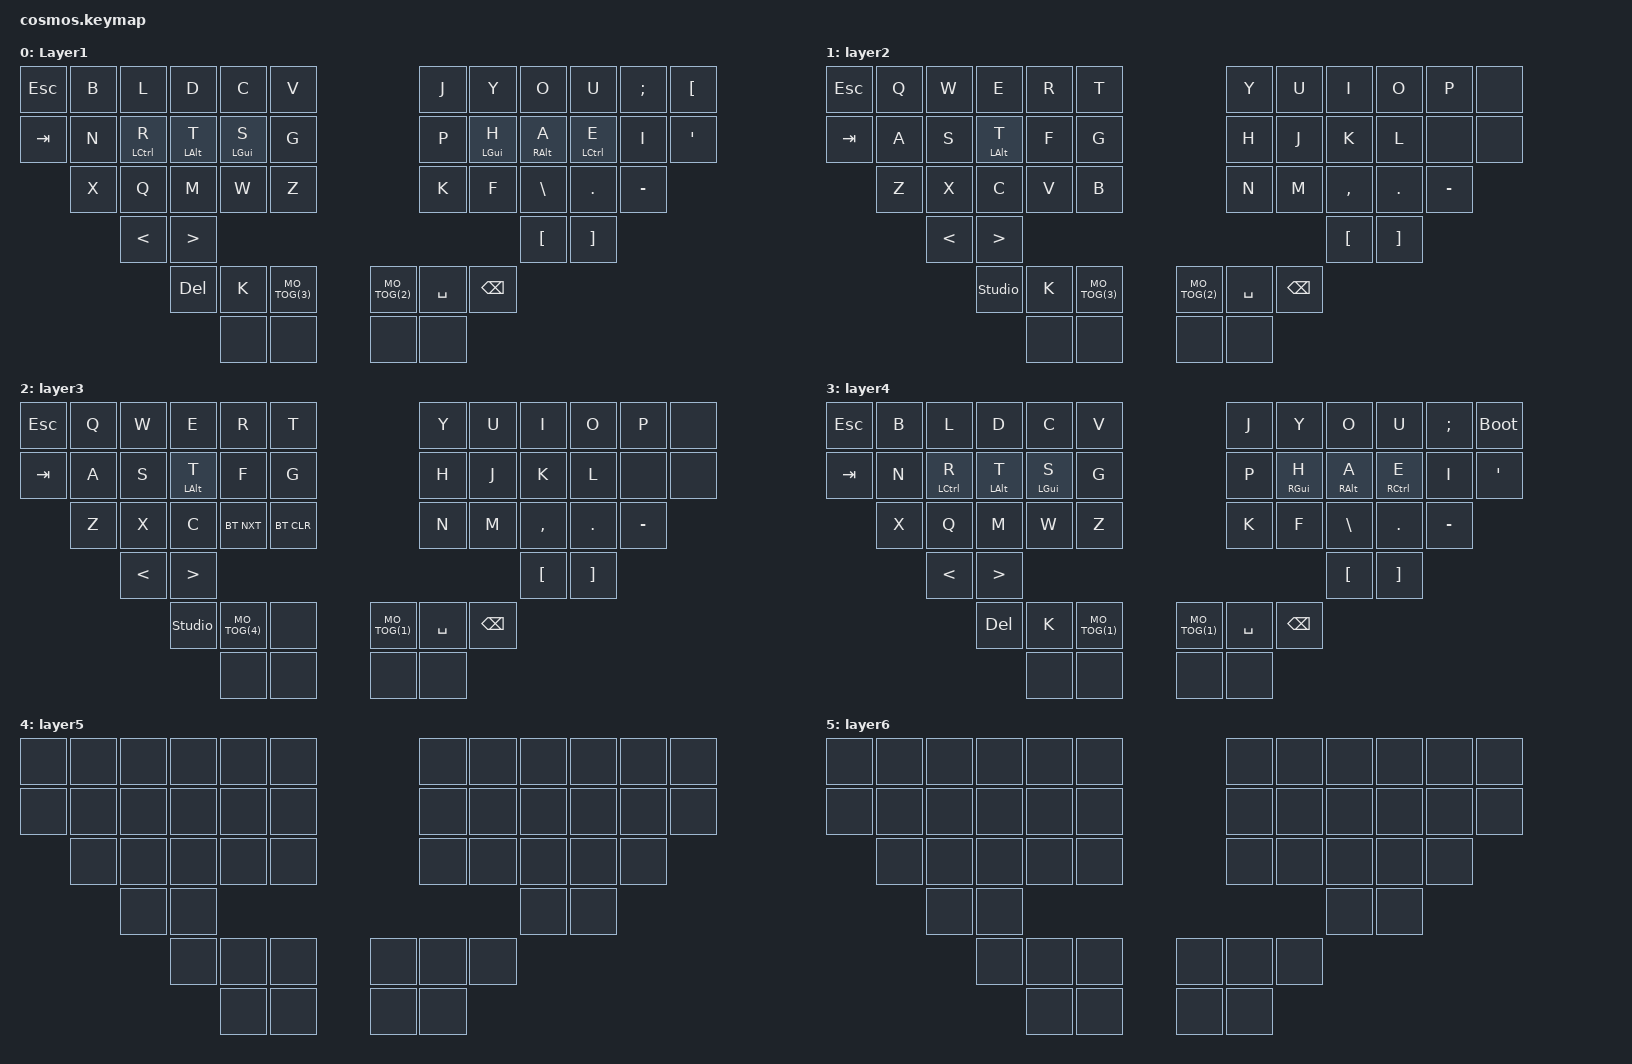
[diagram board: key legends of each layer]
#include <behaviors.dtsi>
#include <dt-bindings/zmk/keys.h>
#include <dt-bindings/zmk/bt.h>
#include <dt-bindings/zmk/mouse.h>
#include "./cosmos.h"

#define MO_TOG(layer) &mo_tog layer layer   // Macro to apply momentary-layer-on-hold/toggle-layer-on-tap to a specific layer

&mt {
    flavor = "tap-preferred";
    tapping_term_ms = <200>;
};

/ { 
	combos {
		compatible = "zmk,combos";

		combo_ent_right {
		    timeout-ms = <50>;
		    key-positions = <RB1 RB2>;
		    bindings = <&kp RET>;
		};
		combo_ent_left {
		    timeout-ms = <50>;
		    key-positions = <LB1 LB2>;
		    bindings = <&kp RET>;
		};

		combo_f {
		    timeout-ms = <50>;
		    key-positions = <LM1 LB1>;
		    bindings = <&kp F>;
		    layers = <0>;
		};
		combo_bksp {
		    timeout-ms = <50>;
		    key-positions = <RB2 RB3>;
		    bindings = <&kp BSPC>;
		};
		combo_bksp_left {
		    timeout-ms = <50>;
		    key-positions = <LB3 LB4>;
		    bindings = <&kp BSPC>;
		};

		combo_del_left {
		    timeout-ms = <50>;
		    key-positions = <LB2 LB3>;
		    bindings = <&kp DEL>;
		};
	};
	
	behaviors {
        bspc_del: backspace_delete {
            compatible = "zmk,behavior-mod-morph";
            #binding-cells = <0>;
            bindings = <&kp BACKSPACE>, <&kp DELETE>;
            mods = <(MOD_LSFT|MOD_RSFT)>;
        };
		mo_tog: behavior_mo_tog {
		    compatible = "zmk,behavior-hold-tap";
		    #binding-cells = <2>;
		    flavor = "hold-preferred";
		    tapping-term-ms = <200>;
		    bindings = <&mo>, <&tog>;
		};
		hm: homerow_mods {
		    compatible = "zmk,behavior-hold-tap";
		    label = "HOMEROW_MODS";
		    #binding-cells = <2>;
		    tapping-term-ms = <200>;
		    quick_tap_ms = <0>;
		    flavor = "tap-preferred";
		    bindings = <&kp>, <&kp>;
		};
		hs: homerow_shifts {
		    compatible = "zmk,behavior-hold-tap";
		    label = "HOMEROW_SHIFTS";
		    #binding-cells = <2>;
		    tapping-term-ms = <150>;
		    quick_tap_ms = <0>;
		    flavor = "balanced";
		    bindings = <&kp>, <&kp>;
		};
		hsl: homerow_shifts_layer {
		    compatible = "zmk,behavior-hold-tap";
		    label = "HOMEROW_SHIFTS_LAYER";
		    #binding-cells = <2>;
		    tapping-term-ms = <150>;
		    quick_tap_ms = <0>;
		    flavor = "balanced";
		    bindings = <&kp>, <&to>;
		};
		td: tapdance {
		    compatible = "zmk,behavior-hold-tap";
		    label = "TAPDANCE";
		    #binding-cells = <2>;
		    tapping-term-ms = <150>;
		    quick_tap_ms = <0>;
		    flavor = "tap-preferred";
		    bindings = <&kp>, <&kp>;
		};
		tl: layertap {
		    compatible = "zmk,behavior-hold-tap";
		    label = "LAYERTAP";
		    #binding-cells = <2>;
		    tapping-term-ms = <150>;
		    quick_tap_ms = <0>;
		    flavor = "tap-preferred";
		    bindings = <&to>, <&kp>;
		};
	};

        keymap {
                compatible = "zmk,keymap";

/*       		default_layer {
		bindings = <
		&kp TAB         &kp C           &kp L           &kp M           &trans 			&trans          &kp F           &kp U           &kp Z           &kp BKSP
		&kp I           &hm LCTL S      &hm LALT R      &hm LGUI T      &trans 			&trans          &hm RGUI N      &hm RALT K      &hm RCTL A      &kp O
		&hs LSHIFT Q    &kp V           &kp W           &kp D           &mt LC(LS(LALT)) SPC    &kp E           &kp H   &       kp Y            &td EXCL DOT    &hs RSHIFT X
          	                                        &mt LC(LS(LALT)) SPC    &trans                  &trans          &kp E
		>;*/
                
                Layer1 { // Layer 1, mallen klar. ska verkställas
                        bindings = <
                                // --------------------------------------------------------------
                             //|  ESC  |   B   |   L   |   D   |   C   |   V   |               |   J   |   Y   |   O   |    U   |    Ö   |    Å   |
                               &kp ESC   &kp B   &kp L   &kp D   &kp C   &kp V                   &kp J   &kp Y   &kp O   &kp U    &kp SEMI &kp LBKT

                             //|  TAB  |   N   |   R   |   T   |   S    |   G   |              |   P   |   H   |   A   |    E   |    I   |    Ä   |
                               &kp TAB   &kp N &hm LCTRL R &hm LALT T   &hm LGUI S   &kp G     &kp P   &hm LGUI H  &hm RALT A  &hm LCTRL E   &kp I &kp SINGLE_QUOTE
                          //      &kp TAB &kp N &hm LCTRL R &hm LALT T &hm LGUI S   &kp G        &none  &none  &none &none &none &none // &kp P &hm LGUI H &hm RALT A  &hm LCTRL E &kp I &kp SINGLE_QUOTE

                             //        |   X   |   Q   |   M   |   W   |   Z   |               |   K   |   F   |   '   |    ,   |    .   |
                                         &kp X   &kp Q   &kp M   &kp W   &kp Z                   &kp K   &kp F &kp BSLH &kp DOT &kp MINUS 

                             //                |   <   |   >   |                                               |   [   |    ]   |
                                                &kp LT   &kp GT                                                  &kp LBKT &kp RBKT


                             //                  |  DEL   |  SHIFT |  To 3 |               |  to 2  | SPACE | BKSP  |
                                                  &kp DEL  &kp K    MO_TOG(3)             MO_TOG(2) &kp SPACE &kp BSPC  

                             //                                  | none | none |               | none | none |
                                                                   &none   &none                  &none &none   
                        >;
                };

                /* Ben vallack kör följande på layer 1. Detta ska ändras till mina behov  left_layer {
		bindings = <
		&trans           &kp ATSN        &td LC(LG(LS(N4))) LS(N3)       &kp DLLR       &trans		&trans  &kp LS(COMMA)   &kp LS(DOT)     &kp CARET       &trans
		&kp TAB          &hm LCTL EQUAL  &hm LALT LA(RBKT)      &hm LGUI LA(LS(RBKT))   &trans 		&trans  &hm RGUI LBRC   &hm RALT RBRC   &hm RCTL PIPE   &kp AMPS
  		&hs LSHIFT TILDE &kp GRAVE 	 &kp LA(LBKT)           &kp LA(LS(LBKT))        &to 0 	        &to 2   &kp LPRN        &kp RPRN        &kp RBKT        &kp RSHIFT
					                                &to 0                   &trans  	&trans  &to 2 
		>;*/

                layer2 { // Specialtecken-lager
                        bindings = <
                                // --------------------------------------------------------------
                             //|  ESC  |   B   |   L   |   #   |  '|'  |   V   |               |   J   |   Y   |   O   |    U   |    Ö   |    Å   |
                               &kp ESC   &kp Q   &kp W   &kp E   &kp R   &kp T                   &kp Y   &kp U   &kp I   &kp O    &kp P    &none

                             //|  TAB  |   N   |   R   |   @   |   /   |   !   |              |   ?   |   (   |   [   |    {   |    <   |    Ä   |
                                &kp TAB  &kp A   &kp S &hm LALT T   &kp F   &kp G                   &kp H   &kp J   &kp K   &kp L    &none    &none

                             //    ;   |   X   |   Q   |   &   |   \   |   Z   |               |   K   |   )   |   ]   |    }   |    >   |
                                         &kp Z   &kp X   &kp C   &kp V   &kp B                   &kp N   &kp M &kp COMMA &kp DOT &kp MINUS 

                             //                |   <   |   >   |                                               |   [   |    ]   |
                                                &kp LT   &kp GT                                                  &kp LBKT &kp RBKT


                             //                  |  stdio ulck   |  SHIFT |  To 3 |               |  to 2  | SPACE | BKSP  |
                                                  &studio_unlock  &kp K    MO_TOG(3)             MO_TOG(2) &kp SPACE &kp BSPC  

                             //                                  | none | none |               | none | none |
                                                                   &none   &none                  &none &none   
                        >;
                };

                layer3 { // Nummer-lager
                        bindings = <
                                // --------------------------------------------------------------
                             //|  ESC  |   B   |   L   |   #   |  '|'  |   V   |               |   DIV   |   7   |   8   |    9   |    -   |    none   |
                               &kp ESC   &kp Q   &kp W   &kp E   &kp R   &kp T                   &kp Y   &kp U   &kp I   &kp O    &kp P    &none

                             //|  TAB  |   N   |   R   |   @   |   /   |   !   |              |   *   |   4   |   5   |    6   |    +   |    none   |
                                &kp TAB  &kp A   &kp S &hm LALT T   &kp F   &kp G                   &kp H   &kp J   &kp K   &kp L    &none    &none

                             //    ;   |   X   |   Q   |   &   | Bluetooth next |  bluetooth clear   |               |   K   |   1   |   2   |    3   |  ENTER |
                                         &kp Z   &kp X   &kp C   &bt BT_NXT   &bt BT_CLR                   &kp N   &kp M &kp COMMA &kp DOT &kp MINUS 

                             //                |   <   |   >   |                                               |   0   |    .   |
                                                &kp LT   &kp GT                                                  &kp LBKT &kp RBKT


                             //                  |  stdio ulck   | To 4 |   |               |  to 1  | SPACE | BKSP  |
                                                  &studio_unlock MO_TOG(4) &none                 MO_TOG(1) &kp SPACE &kp BSPC  

                             //                                  | none | none |               | none | none |
                                                                   &none   &none                  &none &none   
                        >;
                };
                
                layer4 { // Nav layer
                        bindings = <
                                // --------------------------------------------------------------
                             //|  ESC  |   B   |   L   |   D   |   C   |   V   |               |   J   |   Y   |   O   |    U   |    Ö   |   bootloader   |
                               &kp ESC   &kp B   &kp L   &kp D   &kp C   &kp V                   &kp J   &kp Y   &kp O   &kp U    &kp SEMI &bootloader

                             //|  TAB  |   N   |   R   |   T   |   S    |   G   |              |   P   |   H   |   A   |    E   |    I   |    Ä   |
                                &kp TAB &kp N &hm LCTRL R &hm LALT T &hm LGUI S   &kp G        &kp P   &hm RGUI H &hm RALT A &hm RCTL E &kp I &kp SQT

                             //        |   X   |   Q   |   M   |   W   |   Z   |               |   K   |   F   |   '   |    ,   |    .   |
                                         &kp X   &kp Q   &kp M   &kp W   &kp Z                   &kp K   &kp F &kp BSLH &kp DOT &kp MINUS 

                             //                |   <   |   >   |                                               |   [   |    ]   |
                                                &kp LT   &kp GT                                                  &kp LBKT &kp RBKT


                             //                  |  DEL   |  SHIFT |  To 1 |               |  to 1  | SPACE | BKSP  |
                                                  &kp DEL  &kp K    MO_TOG(1)             MO_TOG(1) &kp SPACE &kp BSPC  

                             //                                  | none | none |               | none | none |
                                                                   &none   &none                  &none &none   
                        >;
                };
				layer5 { // Shortcuts layer 1
                        bindings = <
                                // --------------------------------------------------------------
                                 &none   &none   &none   &none   &none   &none                   &none   &none   &none   &none    &none    &none
                                 &none   &none   &none   &none   &none   &none       			 &none   &none 	 &none 	 &none 	  &none    &none
                                         &none   &none   &none   &none   &none                   &none   &none 	 &none 	 &none 	  &none 
                                                 &none   &none                                                   &none   &none
                                                 			&none    &none    &none        &none    &none    &none 
                                                                     &none    &none        &none    &none   
                        >;
                };
				layer6 { // Shortcuts layer 2
                        bindings = <
                                // --------------------------------------------------------------
                                 &none   &none   &none   &none   &none   &none                   &none   &none   &none   &none    &none    &none
                                 &none   &none   &none   &none   &none   &none       			 &none   &none 	 &none 	 &none 	  &none    &none
                                         &none   &none   &none   &none   &none                   &none   &none 	 &none 	 &none 	  &none 
                                                 &none   &none                                                   &none   &none
                                                 			&none    &none    &none        &none    &none    &none 
                                                                     &none    &none        &none    &none   
                        >;
                };
        };
};



/* Ben Vallacks

        keymap {
                compatible = "zmk,keymap";
                
       		default_layer {
		bindings = <
		&kp TAB &kp C &kp L &kp M &trans 						&trans &kp F  &kp U    &kp Z  &kp BKSP
		&kp I &hm LCTL S &hm LALT R &hm LGUI T &trans 			       	&trans  &hm RGUI N &hm RALT K &hm RCTL A &kp O
		&hs LSHIFT Q &kp V &kp W &kp D &mt LC(LS(LALT)) SPC &kp E &kp H  &kp Y &td EXCL DOT &hs RSHIFT X
          				&mt LC(LS(LALT)) SPC &trans &trans &kp E
		>;
		};

       		left_layer {
		bindings = <
		&trans  &kp ATSN   &td LC(LG(LS(N4))) LS(N3) &kp DLLR    &trans		&trans &kp LS(COMMA) &kp LS(DOT) &kp CARET &trans
		&kp TAB    &hm LCTL EQUAL    &hm LALT LA(RBKT)      &hm LGUI LA(LS(RBKT))     &trans 		&trans &hm RGUI LBRC  &hm RALT RBRC &hm RCTL PIPE  &kp AMPS
  		&hs LSHIFT TILDE    &kp GRAVE 	&kp LA(LBKT) &kp LA(LS(LBKT))  &to 0 	&to 2 &kp LPRN &kp RPRN &kp RBKT  &kp RSHIFT
					    &to 0 &trans  					&trans &to 2 
		>;
		};

		right_layer {
		bindings = <
		&trans &kp C_PP &kp C_PREV  &kp C_NEXT  &trans    			&trans  &kp N7 &kp N8 &kp N9 &trans
		&kp TAB  &trans   &hm LALT C_VOL_DN  &hm LGUI C_VOL_UP  &trans  			&trans &hm RGUI N4  &kp N5  &kp N6   &kp EQUAL
		&hsl LSHIFT 4  &kp PRCNT &kp SLASH &kp STAR &to 0 &trans &kp N1 &kp N2 &td DOT N3  &kp MINUS
					  &to 0 &trans  				&trans &trans
		>;
		};

		tri_layer {
		bindings = <
		&trans  &mwh SCROLL_LEFT    &mmv MOVE_UP    &mwh SCROLL_RIGHT    &trans &trans    &kp LC(LS(TAB))   &kp RC(TAB) &kp LG(LBKT) &trans
		&kp TAB &mmv MOVE_LEFT &mmv MOVE_DOWN &mmv MOVE_RIGHT &trans  						&trans &kp DOWN  &hm RALT UP &hm RCTL RIGHT &kp LG(RBKT)
		&kp LSHIFT &mkp RCLK  &mwh SCROLL_UP &mwh SCROLL_DOWN &to 0   				&kp RGUI &td HOME PG_DN  &td END PG_UP  &trans &kp RSHIFT  
					 &to 0 &trans &trans &kp RGUI 
		>;
		};
		bt {
		bindings = <
		&trans  &trans &trans &trans &trans &trans &trans &trans &trans &trans 
		&bootloader  &trans &trans &trans &trans &trans &trans &trans &trans &trans 
		&bt BT_PRV  &bt BT_NXT &bt BT_CLR &trans &to 0   				&to 1 &trans  &trans  &trans &trans   
					 &to 0 &trans  					&trans &to 1 
		>;
		};

*/
